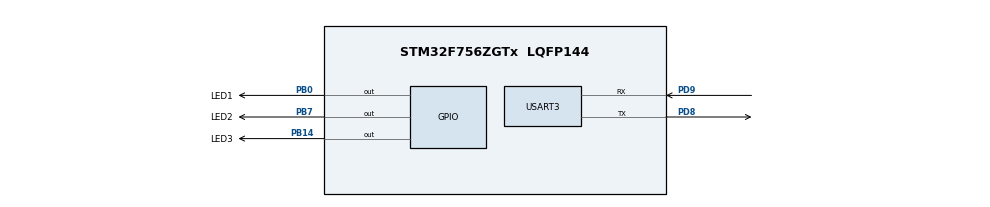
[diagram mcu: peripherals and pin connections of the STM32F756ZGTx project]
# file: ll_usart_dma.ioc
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Dma.Request0=USART3_RX
Dma.USART3_RX.0.Direction=DMA_PERIPH_TO_MEMORY
Dma.USART3_RX.0.FIFOMode=DMA_FIFOMODE_DISABLE
Dma.USART3_RX.0.Instance=DMA1_Stream1
Dma.USART3_RX.0.MemDataAlignment=DMA_MDATAALIGN_BYTE
Dma.USART3_RX.0.MemInc=DMA_MINC_ENABLE
Dma.USART3_RX.0.Mode=DMA_NORMAL
Dma.USART3_RX.0.PeriphDataAlignment=DMA_PDATAALIGN_BYTE
Dma.USART3_RX.0.PeriphInc=DMA_PINC_DISABLE
Dma.USART3_RX.0.Priority=DMA_PRIORITY_LOW
Mcu.Family=STM32F7
Mcu.Name=STM32F756ZGTx
Mcu.Package=LQFP144
NVIC.DMA1_Stream1_IRQn=true\:4\:0\:true\:false\:true\:false\:true\:true
NVIC.PriorityGroup=NVIC_PRIORITYGROUP_4
PB0.GPIO_Label=LED1
PB0.Signal=GPIO_Output
PB14.GPIO_Label=LED3
PB14.Signal=GPIO_Output
PB7.GPIO_Label=LED2
PB7.Signal=GPIO_Output
PD8.Mode=Asynchronous
PD8.Signal=USART3_TX
PD9.Mode=Asynchronous
PD9.Signal=USART3_RX
ProjectManager.HeapSize=0x200
ProjectManager.StackSize=0x400
ProjectManager.TargetToolchain=STM32CubeIDE
RCC.AHBFreq_Value=64000000
RCC.APB1CLKDivider=RCC_HCLK_DIV2
RCC.APB1Freq_Value=32000000
RCC.APB1TimFreq_Value=64000000
RCC.APB2Freq_Value=64000000
RCC.APB2TimFreq_Value=64000000
RCC.CortexFreq_Value=64000000
RCC.HCLKFreq_Value=64000000
RCC.HSE_VALUE=25000000
RCC.HSI_VALUE=16000000
RCC.LSE_VALUE=32768
RCC.PLLM=8
RCC.PLLN=64
RCC.SYSCLKFreq_VALUE=64000000
RCC.SYSCLKSource=RCC_SYSCLKSOURCE_PLLCLK
RCC.USBFreq_Value=64000000
RCC.VCOOutputFreq_Value=128000000
USART3.VirtualMode-Asynchronous=VM_ASYNC
board=custom

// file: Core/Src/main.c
/* USER CODE BEGIN Header */
/**
 ******************************************************************************
 * @file           : main.c
 * @brief          : Main program body
 ******************************************************************************
 * @attention
 *
 * Copyright (c) 2023 STMicroelectronics.
 * All rights reserved.
 *
 * This software is licensed under terms that can be found in the LICENSE file
 * in the root directory of this software component.
 * If no LICENSE file comes with this software, it is provided AS-IS.
 *
 ******************************************************************************
 */
/* USER CODE END Header */
#include "main.h"

/* USER CODE BEGIN PV */

buffer_t rx_buffer = {0};
/* USER CODE END PV */

void SystemClock_Config(void);
static void MX_GPIO_Init(void);
static void MX_DMA_Init(void);
static void MX_USART3_UART_Init(void);
/* USER CODE BEGIN PFP */
void USART3_Init();
/* USER CODE END PFP */

int main(void)
{

  /* MCU Configuration--------------------------------------------------------*/

  /* Reset of all peripherals, Initializes the Flash interface and the Systick. */
  LL_APB1_GRP1_EnableClock(LL_APB1_GRP1_PERIPH_PWR);
  LL_APB2_GRP1_EnableClock(LL_APB2_GRP1_PERIPH_SYSCFG);

  /* System interrupt init*/
  NVIC_SetPriorityGrouping(NVIC_PRIORITYGROUP_4);

  /* SysTick_IRQn interrupt configuration */
  NVIC_SetPriority(SysTick_IRQn, NVIC_EncodePriority(NVIC_GetPriorityGrouping(),15, 0));

  /* Configure the system clock */
  SystemClock_Config();

  /* Initialize all configured peripherals */
  MX_GPIO_Init();
  MX_DMA_Init();
  MX_USART3_UART_Init();
  /* USER CODE BEGIN 2 */

  LL_DMA_EnableIT_TC(DMA1, LL_DMA_STREAM_1);
  LL_DMA_ConfigAddresses(DMA1, LL_DMA_STREAM_1, LL_USART_DMA_GetRegAddr(USART3, LL_USART_DMA_REG_DATA_RECEIVE), (uint32_t)rx_buffer.data, LL_DMA_GetDataTransferDirection(DMA1, LL_DMA_STREAM_1));
  LL_DMA_SetDataLength(DMA1, LL_DMA_STREAM_1, sizeof(rx_buffer.data));
  LL_USART_EnableDMAReq_RX(USART3);
  LL_DMA_EnableStream(DMA1, LL_DMA_STREAM_1);
  /* USER CODE END 2 */

  /* Infinite loop */
  while (1)
  {
  }

}

void SystemClock_Config(void)
{
  LL_FLASH_SetLatency(LL_FLASH_LATENCY_2);
  while(LL_FLASH_GetLatency()!= LL_FLASH_LATENCY_2)
  {
  }
  LL_PWR_SetRegulVoltageScaling(LL_PWR_REGU_VOLTAGE_SCALE3);

  LL_PWR_DisableOverDriveMode();
  LL_RCC_HSI_SetCalibTrimming(16);
  LL_RCC_HSI_Enable();

   /* Wait till HSI is ready */
  while(LL_RCC_HSI_IsReady() != 1)
  {

  }
  LL_RCC_PLL_ConfigDomain_SYS(LL_RCC_PLLSOURCE_HSI, LL_RCC_PLLM_DIV_8, 64, LL_RCC_PLLP_DIV_2);
  LL_RCC_PLL_Enable();

   /* Wait till PLL is ready */
  while(LL_RCC_PLL_IsReady() != 1)
  {

  }
  LL_RCC_SetAHBPrescaler(LL_RCC_SYSCLK_DIV_1);
  LL_RCC_SetAPB1Prescaler(LL_RCC_APB1_DIV_2);
  LL_RCC_SetAPB2Prescaler(LL_RCC_APB2_DIV_1);
  LL_RCC_SetSysClkSource(LL_RCC_SYS_CLKSOURCE_PLL);

   /* Wait till System clock is ready */
  while(LL_RCC_GetSysClkSource() != LL_RCC_SYS_CLKSOURCE_STATUS_PLL)
  {

  }
  LL_Init1msTick(64000000);
  LL_SetSystemCoreClock(64000000);
}

static void MX_USART3_UART_Init(void)
{

  LL_USART_InitTypeDef USART_InitStruct = {0};

  LL_GPIO_InitTypeDef GPIO_InitStruct = {0};

  LL_RCC_SetUSARTClockSource(LL_RCC_USART3_CLKSOURCE_PCLK1);

  /* Peripheral clock enable */
  LL_APB1_GRP1_EnableClock(LL_APB1_GRP1_PERIPH_USART3);

  LL_AHB1_GRP1_EnableClock(LL_AHB1_GRP1_PERIPH_GPIOD);
  /**USART3 GPIO Configuration
  PD8   ------> USART3_TX
  PD9   ------> USART3_RX
  */
  GPIO_InitStruct.Pin = LL_GPIO_PIN_8;
  GPIO_InitStruct.Mode = LL_GPIO_MODE_ALTERNATE;
  GPIO_InitStruct.Speed = LL_GPIO_SPEED_FREQ_VERY_HIGH;
  GPIO_InitStruct.OutputType = LL_GPIO_OUTPUT_PUSHPULL;
  GPIO_InitStruct.Pull = LL_GPIO_PULL_NO;
  GPIO_InitStruct.Alternate = LL_GPIO_AF_7;
  LL_GPIO_Init(GPIOD, &GPIO_InitStruct);

  GPIO_InitStruct.Pin = LL_GPIO_PIN_9;
  GPIO_InitStruct.Mode = LL_GPIO_MODE_ALTERNATE;
  GPIO_InitStruct.Speed = LL_GPIO_SPEED_FREQ_VERY_HIGH;
  GPIO_InitStruct.OutputType = LL_GPIO_OUTPUT_PUSHPULL;
  GPIO_InitStruct.Pull = LL_GPIO_PULL_NO;
  GPIO_InitStruct.Alternate = LL_GPIO_AF_7;
  LL_GPIO_Init(GPIOD, &GPIO_InitStruct);

  /* USART3 DMA Init */

  /* USART3_RX Init */
  LL_DMA_SetChannelSelection(DMA1, LL_DMA_STREAM_1, LL_DMA_CHANNEL_4);

  LL_DMA_SetDataTransferDirection(DMA1, LL_DMA_STREAM_1, LL_DMA_DIRECTION_PERIPH_TO_MEMORY);

  LL_DMA_SetStreamPriorityLevel(DMA1, LL_DMA_STREAM_1, LL_DMA_PRIORITY_LOW);

  LL_DMA_SetMode(DMA1, LL_DMA_STREAM_1, LL_DMA_MODE_NORMAL);

  LL_DMA_SetPeriphIncMode(DMA1, LL_DMA_STREAM_1, LL_DMA_PERIPH_NOINCREMENT);

  LL_DMA_SetMemoryIncMode(DMA1, LL_DMA_STREAM_1, LL_DMA_MEMORY_INCREMENT);

  LL_DMA_SetPeriphSize(DMA1, LL_DMA_STREAM_1, LL_DMA_PDATAALIGN_BYTE);

  LL_DMA_SetMemorySize(DMA1, LL_DMA_STREAM_1, LL_DMA_MDATAALIGN_BYTE);

  LL_DMA_DisableFifoMode(DMA1, LL_DMA_STREAM_1);

  USART_InitStruct.BaudRate = 115200;
  USART_InitStruct.DataWidth = LL_USART_DATAWIDTH_8B;
  USART_InitStruct.StopBits = LL_USART_STOPBITS_1;
  USART_InitStruct.Parity = LL_USART_PARITY_NONE;
  USART_InitStruct.TransferDirection = LL_USART_DIRECTION_TX_RX;
  USART_InitStruct.HardwareFlowControl = LL_USART_HWCONTROL_NONE;
  USART_InitStruct.OverSampling = LL_USART_OVERSAMPLING_16;
  LL_USART_Init(USART3, &USART_InitStruct);
  LL_USART_ConfigAsyncMode(USART3);
  LL_USART_Enable(USART3);

}

static void MX_DMA_Init(void)
{

  /* Init with LL driver */
  /* DMA controller clock enable */
  LL_AHB1_GRP1_EnableClock(LL_AHB1_GRP1_PERIPH_DMA1);

  /* DMA interrupt init */
  /* DMA1_Stream1_IRQn interrupt configuration */
  NVIC_SetPriority(DMA1_Stream1_IRQn, NVIC_EncodePriority(NVIC_GetPriorityGrouping(),4, 0));
  NVIC_EnableIRQ(DMA1_Stream1_IRQn);

}

static void MX_GPIO_Init(void)
{
  LL_GPIO_InitTypeDef GPIO_InitStruct = {0};

  /* GPIO Ports Clock Enable */
  LL_AHB1_GRP1_EnableClock(LL_AHB1_GRP1_PERIPH_GPIOB);
  LL_AHB1_GRP1_EnableClock(LL_AHB1_GRP1_PERIPH_GPIOD);

  /**/
  LL_GPIO_ResetOutputPin(LED1_GPIO_Port, LED1_Pin);

  /**/
  LL_GPIO_ResetOutputPin(LED3_GPIO_Port, LED3_Pin);

  /**/
  LL_GPIO_ResetOutputPin(LED2_GPIO_Port, LED2_Pin);

  /**/
  GPIO_InitStruct.Pin = LED1_Pin;
  GPIO_InitStruct.Mode = LL_GPIO_MODE_OUTPUT;
  GPIO_InitStruct.Speed = LL_GPIO_SPEED_FREQ_LOW;
  GPIO_InitStruct.OutputType = LL_GPIO_OUTPUT_PUSHPULL;
  GPIO_InitStruct.Pull = LL_GPIO_PULL_NO;
  LL_GPIO_Init(LED1_GPIO_Port, &GPIO_InitStruct);

  /**/
  GPIO_InitStruct.Pin = LED3_Pin;
  GPIO_InitStruct.Mode = LL_GPIO_MODE_OUTPUT;
  GPIO_InitStruct.Speed = LL_GPIO_SPEED_FREQ_LOW;
  GPIO_InitStruct.OutputType = LL_GPIO_OUTPUT_PUSHPULL;
  GPIO_InitStruct.Pull = LL_GPIO_PULL_NO;
  LL_GPIO_Init(LED3_GPIO_Port, &GPIO_InitStruct);

  /**/
  GPIO_InitStruct.Pin = LED2_Pin;
  GPIO_InitStruct.Mode = LL_GPIO_MODE_OUTPUT;
  GPIO_InitStruct.Speed = LL_GPIO_SPEED_FREQ_LOW;
  GPIO_InitStruct.OutputType = LL_GPIO_OUTPUT_PUSHPULL;
  GPIO_InitStruct.Pull = LL_GPIO_PULL_NO;
  LL_GPIO_Init(LED2_GPIO_Port, &GPIO_InitStruct);

}

void Error_Handler(void)
{
  __disable_irq();
  while (1)
  {
  }
}
